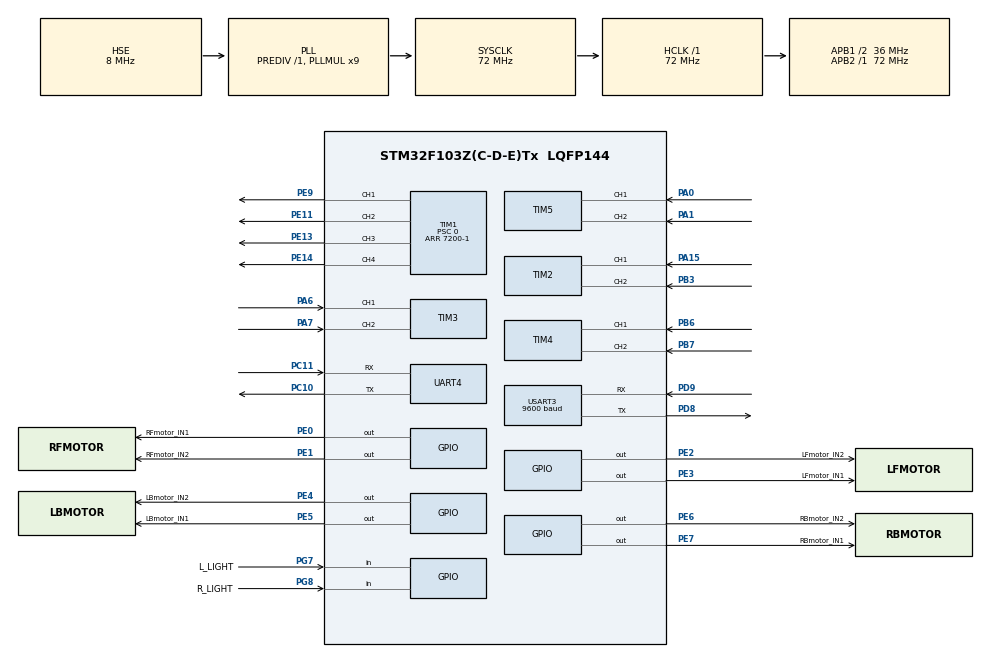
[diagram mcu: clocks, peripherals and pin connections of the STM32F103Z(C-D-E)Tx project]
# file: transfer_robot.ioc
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FREERTOS.Tasks01=defaultTask,0,128,StartDefaultTask,Default,NULL,Dynamic,NULL,NULL
Mcu.Family=STM32F1
Mcu.Name=STM32F103Z(C-D-E)Tx
Mcu.Package=LQFP144
NVIC.PriorityGroup=NVIC_PRIORITYGROUP_4
NVIC.TIM6_IRQn=true\:5\:0\:false\:false\:true\:true\:true\:true\:true
NVIC.TIM8_UP_IRQn=true\:15\:0\:false\:false\:true\:false\:false\:true\:true
NVIC.TimeBase=TIM8_UP_IRQn
NVIC.TimeBaseIP=TIM8
NVIC.UART4_IRQn=true\:5\:0\:false\:false\:true\:true\:true\:true\:true
OSC_IN.Mode=HSE-External-Oscillator
OSC_IN.Signal=RCC_OSC_IN
OSC_OUT.Mode=HSE-External-Oscillator
OSC_OUT.Signal=RCC_OSC_OUT
PA0-WKUP.Signal=S_TIM5_CH1
PA1.Signal=S_TIM5_CH2
PA13.Mode=Serial_Wire
PA13.Signal=SYS_JTMS-SWDIO
PA14.Mode=Serial_Wire
PA14.Signal=SYS_JTCK-SWCLK
PA15.Signal=S_TIM2_CH1_ETR
PA6.Signal=S_TIM3_CH1
PA7.Signal=S_TIM3_CH2
PB3.Signal=S_TIM2_CH2
PB6.Signal=S_TIM4_CH1
PB7.Signal=S_TIM4_CH2
PC10.Mode=Asynchronous
PC10.Signal=UART4_TX
PC11.Mode=Asynchronous
PC11.Signal=UART4_RX
PC14-OSC32_IN.Mode=LSE-External-Oscillator
PC14-OSC32_IN.Signal=RCC_OSC32_IN
PC15-OSC32_OUT.Mode=LSE-External-Oscillator
PC15-OSC32_OUT.Signal=RCC_OSC32_OUT
PD8.Mode=Asynchronous
PD8.Signal=USART3_TX
PD9.Mode=Asynchronous
PD9.Signal=USART3_RX
PE0.GPIO_Label=RFmotor_IN1
PE0.Signal=GPIO_Output
PE1.GPIO_Label=RFmotor_IN2
PE1.Signal=GPIO_Output
PE11.Signal=S_TIM1_CH2
PE13.Signal=S_TIM1_CH3
PE14.Signal=S_TIM1_CH4
PE2.GPIO_Label=LFmotor_IN2
PE2.Signal=GPIO_Output
PE3.GPIO_Label=LFmotor_IN1
PE3.Signal=GPIO_Output
PE4.GPIO_Label=LBmotor_IN2
PE4.Signal=GPIO_Output
PE5.GPIO_Label=LBmotor_IN1
PE5.Signal=GPIO_Output
PE6.GPIO_Label=RBmotor_IN2
PE6.Signal=GPIO_Output
PE7.GPIO_Label=RBmotor_IN1
PE7.Signal=GPIO_Output
PE9.Signal=S_TIM1_CH1
PG7.GPIO_Label=L_LIGHT
PG7.Signal=GPIO_Input
PG8.GPIO_Label=R_LIGHT
PG8.Signal=GPIO_Input
ProjectManager.HeapSize=0x200
ProjectManager.StackSize=0x400
ProjectManager.TargetToolchain=MDK-ARM V5.32
RCC.AHBFreq_Value=72000000
RCC.APB1CLKDivider=RCC_HCLK_DIV2
RCC.APB1Freq_Value=36000000
RCC.APB1TimFreq_Value=72000000
RCC.APB2Freq_Value=72000000
RCC.APB2TimFreq_Value=72000000
RCC.HCLKFreq_Value=72000000
RCC.PLLMUL=RCC_PLL_MUL9
RCC.PLLSourceVirtual=RCC_PLLSOURCE_HSE
RCC.RTCClockSelection=RCC_RTCCLKSOURCE_LSE
RCC.SYSCLKFreq_VALUE=72000000
RCC.SYSCLKSource=RCC_SYSCLKSOURCE_PLLCLK
RCC.USBFreq_Value=72000000
SH.S_TIM1_CH1.0=TIM1_CH1,PWM Generation1 CH1
SH.S_TIM1_CH2.0=TIM1_CH2,PWM Generation2 CH2
SH.S_TIM1_CH3.0=TIM1_CH3,PWM Generation3 CH3
SH.S_TIM1_CH4.0=TIM1_CH4,PWM Generation4 CH4
SH.S_TIM2_CH1_ETR.0=TIM2_CH1,Encoder_Interface
SH.S_TIM2_CH2.0=TIM2_CH2,Encoder_Interface
SH.S_TIM3_CH1.0=TIM3_CH1,Encoder_Interface
SH.S_TIM3_CH2.0=TIM3_CH2,Encoder_Interface
SH.S_TIM4_CH1.0=TIM4_CH1,Encoder_Interface
SH.S_TIM4_CH2.0=TIM4_CH2,Encoder_Interface
SH.S_TIM5_CH1.0=TIM5_CH1,Encoder_Interface
SH.S_TIM5_CH2.0=TIM5_CH2,Encoder_Interface
TIM1.AutoReloadPreload=TIM_AUTORELOAD_PRELOAD_ENABLE
TIM1.Channel-PWM\ Generation1\ CH1=TIM_CHANNEL_1
TIM1.Channel-PWM\ Generation2\ CH2=TIM_CHANNEL_2
TIM1.Channel-PWM\ Generation3\ CH3=TIM_CHANNEL_3
TIM1.Channel-PWM\ Generation4\ CH4=TIM_CHANNEL_4
TIM1.OCFastMode_PWM-PWM\ Generation1\ CH1=TIM_OCFAST_DISABLE
TIM1.OCFastMode_PWM-PWM\ Generation2\ CH2=TIM_OCFAST_DISABLE
TIM1.OCFastMode_PWM-PWM\ Generation3\ CH3=TIM_OCFAST_DISABLE
TIM1.OCFastMode_PWM-PWM\ Generation4\ CH4=TIM_OCFAST_DISABLE
TIM1.Period=7200-1
TIM1.Prescaler=0
TIM2.EncoderMode=TIM_ENCODERMODE_TI12
TIM6.AutoReloadPreload=TIM_AUTORELOAD_PRELOAD_ENABLE
TIM6.Period=100-1
TIM6.Prescaler=7200-1
UART4.VirtualMode=Asynchronous
USART3.BaudRate=9600
USART3.VirtualMode=VM_ASYNC
VP_FREERTOS_VS_CMSIS_V1.Mode=CMSIS_V1
VP_RTC_VS_RTC_Activate.Mode=RTC_Enabled
VP_SYS_VS_tim8.Mode=TIM8
VP_TIM1_VS_ClockSourceINT.Mode=Internal
VP_TIM6_VS_ClockSourceINT.Mode=Enable_Timer
board=custom

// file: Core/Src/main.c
/* USER CODE BEGIN Header */
/**
  ******************************************************************************
  * @file           : main.c
  * @brief          : Main program body
  ******************************************************************************
  * @attention
  *
  * Copyright (c) 2023 STMicroelectronics.
  * All rights reserved.
  *
  * This software is licensed under terms that can be found in the LICENSE file
  * in the root directory of this software component.
  * If no LICENSE file comes with this software, it is provided AS-IS.
  *
  ******************************************************************************
  */
/* USER CODE END Header */
#include "main.h"
#include "cmsis_os.h"
#include "rtc.h"
#include "tim.h"
#include "usart.h"
#include "gpio.h"

/* USER CODE BEGIN Includes */
#include "encoder.h"
#include "bsp_init.h"
/* USER CODE END Includes */

void SystemClock_Config(void);
void MX_FREERTOS_Init(void);

int main(void)
{

  /* MCU Configuration--------------------------------------------------------*/

  /* Reset of all peripherals, Initializes the Flash interface and the Systick. */
  HAL_Init();

  /* Configure the system clock */
  SystemClock_Config();

  /* Initialize all configured peripherals */
  MX_GPIO_Init();
  MX_RTC_Init();
  MX_TIM1_Init();
  MX_TIM2_Init();
  MX_TIM3_Init();
  MX_TIM4_Init();
  MX_TIM5_Init();
  MX_UART4_Init();
  MX_USART3_UART_Init();
  MX_TIM6_Init();
  /* USER CODE BEGIN 2 */
bsp_init();
  /* USER CODE END 2 */

  /* Call init function for freertos objects (in freertos.c) */
  MX_FREERTOS_Init();

  /* Start scheduler */
  osKernelStart();
  /* We should never get here as control is now taken by the scheduler */
  /* Infinite loop */
  while (1)
  {

  }
}

void SystemClock_Config(void)
{
  RCC_OscInitTypeDef RCC_OscInitStruct = {0};
  RCC_ClkInitTypeDef RCC_ClkInitStruct = {0};
  RCC_PeriphCLKInitTypeDef PeriphClkInit = {0};

  /** Initializes the RCC Oscillators according to the specified parameters
  * in the RCC_OscInitTypeDef structure.
  */
  RCC_OscInitStruct.OscillatorType = RCC_OSCILLATORTYPE_HSE|RCC_OSCILLATORTYPE_LSE;
  RCC_OscInitStruct.HSEState = RCC_HSE_ON;
  RCC_OscInitStruct.HSEPredivValue = RCC_HSE_PREDIV_DIV1;
  RCC_OscInitStruct.LSEState = RCC_LSE_ON;
  RCC_OscInitStruct.HSIState = RCC_HSI_ON;
  RCC_OscInitStruct.PLL.PLLState = RCC_PLL_ON;
  RCC_OscInitStruct.PLL.PLLSource = RCC_PLLSOURCE_HSE;
  RCC_OscInitStruct.PLL.PLLMUL = RCC_PLL_MUL9;
  if (HAL_RCC_OscConfig(&RCC_OscInitStruct) != HAL_OK)
  {
    Error_Handler();
  }

  /** Initializes the CPU, AHB and APB buses clocks
  */
  RCC_ClkInitStruct.ClockType = RCC_CLOCKTYPE_HCLK|RCC_CLOCKTYPE_SYSCLK
                              |RCC_CLOCKTYPE_PCLK1|RCC_CLOCKTYPE_PCLK2;
  RCC_ClkInitStruct.SYSCLKSource = RCC_SYSCLKSOURCE_PLLCLK;
  RCC_ClkInitStruct.AHBCLKDivider = RCC_SYSCLK_DIV1;
  RCC_ClkInitStruct.APB1CLKDivider = RCC_HCLK_DIV2;
  RCC_ClkInitStruct.APB2CLKDivider = RCC_HCLK_DIV1;

  if (HAL_RCC_ClockConfig(&RCC_ClkInitStruct, FLASH_LATENCY_2) != HAL_OK)
  {
    Error_Handler();
  }
  PeriphClkInit.PeriphClockSelection = RCC_PERIPHCLK_RTC;
  PeriphClkInit.RTCClockSelection = RCC_RTCCLKSOURCE_LSE;
  if (HAL_RCCEx_PeriphCLKConfig(&PeriphClkInit) != HAL_OK)
  {
    Error_Handler();
  }
}

void HAL_TIM_PeriodElapsedCallback(TIM_HandleTypeDef *htim)
{
  if (htim->Instance == TIM8) {
    HAL_IncTick();
  }
  /* USER CODE BEGIN Callback 1 */
	  if (htim->Instance == TIM6) {
    pid_control();
		Set_Pwm();

  }
		if (htim->Instance == TIM1) {

  }
  /* USER CODE END Callback 1 */
}

void Error_Handler(void)
{
  __disable_irq();
  while (1)
  {
  }
}

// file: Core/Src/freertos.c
/* USER CODE BEGIN Header */
/**
  ******************************************************************************
  * File Name          : freertos.c
  * Description        : Code for freertos applications
  ******************************************************************************
  * @attention
  *
  * Copyright (c) 2023 STMicroelectronics.
  * All rights reserved.
  *
  * This software is licensed under terms that can be found in the LICENSE file
  * in the root directory of this software component.
  * If no LICENSE file comes with this software, it is provided AS-IS.
  *
  ******************************************************************************
  */
/* USER CODE END Header */

#include "FreeRTOS.h"
#include "task.h"
#include "main.h"
#include "cmsis_os.h"

/* USER CODE BEGIN Includes */
#include "encoder.h"
#include "bsp_motor.h"
#include "encoder.h"
/* USER CODE END Includes */

osThreadId defaultTaskHandle;

void StartDefaultTask(void const * argument);

void MX_FREERTOS_Init(void); /* (MISRA C 2004 rule 8.1) */

/* GetIdleTaskMemory prototype (linked to static allocation support) */
void vApplicationGetIdleTaskMemory( StaticTask_t **ppxIdleTaskTCBBuffer, StackType_t **ppxIdleTaskStackBuffer, uint32_t *pulIdleTaskStackSize );

/* USER CODE BEGIN GET_IDLE_TASK_MEMORY */
static StaticTask_t xIdleTaskTCBBuffer;
static StackType_t xIdleStack[configMINIMAL_STACK_SIZE];

void vApplicationGetIdleTaskMemory( StaticTask_t **ppxIdleTaskTCBBuffer, StackType_t **ppxIdleTaskStackBuffer, uint32_t *pulIdleTaskStackSize )
{
  *ppxIdleTaskTCBBuffer = &xIdleTaskTCBBuffer;
  *ppxIdleTaskStackBuffer = &xIdleStack[0];
  *pulIdleTaskStackSize = configMINIMAL_STACK_SIZE;
  /* place for user code */
}
/* USER CODE END GET_IDLE_TASK_MEMORY */

void MX_FREERTOS_Init(void) {

  /* Create the thread(s) */
  /* definition and creation of defaultTask */
  osThreadDef(defaultTask, StartDefaultTask, osPriorityNormal, 0, 128);
  defaultTaskHandle = osThreadCreate(osThread(defaultTask), NULL);

}

/* USER CODE BEGIN Header_StartDefaultTask */
/**
  * @brief  Function implementing the defaultTask thread.
  * @param  argument: Not used
  * @retval None
  */
int tasktt=0;
/* USER CODE END Header_StartDefaultTask */
void StartDefaultTask(void const * argument)
{
  /* USER CODE BEGIN StartDefaultTask */
  /* Infinite loop */
  for(;;)
  {
		setspeed(40,40,40,40);
    osDelay(5);
  }
  /* USER CODE END StartDefaultTask */
}
